AUTOSAR XML (schema 00049)
package /Application/DltConfig
  dlt log channel to process mapping DltLogChannelToProcessMapping_SOA_Power_TO_SOA_Power: dlt-log-channel=SOA_Power, process=SOA_Power
package /Application/Executable
  executable SOA_Power: category=APPLICATION_LEVEL, logging-behavior=USES-LOGGING, reporting-behavior=REPORTS-EXECUTION-STATE, version=1.0.0
    root sw component prototype AA: application-type=SOA_Power
package /Application/Manifest
  6 x service instance to port prototype mapping, all with process=SOA_Power:
    SOA_Power_AA_PPort_SOA_Power: port-prototype=AA.PPort_SOA_Power, service-instance=Provider_SoaPower
    SOA_Power_AA_RPort_Zone{1..4}RsvA: port-prototype=AA.RPort_Zone{1..4}RsvA, service-instance=Consumer_Zone{1..4}Rsv
    SOA_Power_AA_RPort_Zone5Power: port-prototype=AA.RPort_Zone5Power, service-instance=Consumer_Zone5Power
package /Application/Package/SOA_Power/SoftwareCluster_1_0_0
  software cluster SOA_Power_SoftwareCluster: category=APPLICATION_LAYER, contained-ar-element=SOA_Power, contained-package-element=[SOA_Power_AA_PPort_SOA_Power, SOA_Power_AA_RPort_Zone1RsvA, SOA_Power_AA_RPort_Zone2RsvA, SOA_Power_AA_RPort_Zone3RsvA, SOA_Power_AA_RPort_Zone4RsvA], contained-process=SOA_Power, vendor-id=79, vendor-signature=ParaCertificate, version=1.0.0
package /Application/Package/SOA_Power/SoftwareCluster_1_0_1
  software cluster SOA_Power_SoftwareCluster: category=APPLICATION_LAYER, contained-ar-element=SOA_Power, contained-package-element=[SOA_Power_AA_PPort_SOA_Power, SOA_Power_AA_RPort_Zone1RsvA, SOA_Power_AA_RPort_Zone2RsvA, SOA_Power_AA_RPort_Zone3RsvA, SOA_Power_AA_RPort_Zone4RsvA], contained-process=SOA_Power, vendor-id=79, vendor-signature=ParaCertificate, version=1.0.1
package /Application/Package/SOA_Power/SoftwareCluster_1_0_2
  software cluster SOA_Power_SoftwareCluster: category=APPLICATION_LAYER, contained-ar-element=SOA_Power, contained-package-element=[SOA_Power_AA_PPort_SOA_Power, SOA_Power_AA_RPort_Zone1RsvA, SOA_Power_AA_RPort_Zone2RsvA, SOA_Power_AA_RPort_Zone3RsvA, SOA_Power_AA_RPort_Zone4RsvA], contained-process=SOA_Power, vendor-id=79, vendor-signature=ParaCertificate, version=1.0.2
package /Application/Package/SOA_Power/SoftwarePackage
  software package SOA_Power_InstallSoftwarePackage_1_0_0: action-type=INSTALL, compressed-software-package-size=0, maximum-supported-ucm-version=1.0.0, minimum-supported-ucm-version=1.0.0, packager-id=79, packager-signature=ParaCertificate, post-verification-reboot=false, pre-activate=SC.Off, pre-activation-reboot=false, software-cluster=SoftwareCluster_1_0_0/SOA_Power_SoftwareCluster, uncompressed-software-cluster-size=0, verify=SC.Verify
  software package SOA_Power_RemoveSoftwarePackage_1_0_2: action-type=REMOVE, compressed-software-package-size=0, maximum-supported-ucm-version=1.0.0, minimum-supported-ucm-version=1.0.0, packager-id=79, packager-signature=ParaCertificate, post-verification-reboot=false, pre-activate=SC.Off, pre-activation-reboot=false, software-cluster=SoftwareCluster_1_0_2/SOA_Power_SoftwareCluster, uncompressed-software-cluster-size=0, verify=SC.Verify
  software package SOA_Power_UpdateSoftwarePackage_1_0_1: action-type=UPDATE, compressed-software-package-size=0, maximum-supported-ucm-version=1.0.0, minimum-supported-ucm-version=1.0.0, packager-id=79, packager-signature=ParaCertificate, post-verification-reboot=false, pre-activate=SC.Off, pre-activation-reboot=false, software-cluster=SoftwareCluster_1_0_1/SOA_Power_SoftwareCluster, uncompressed-software-cluster-size=0, verify=SC.Verify
package /Application/Package/SOA_Power/VehiclePackage
  vehicle package SOA_Power_InstallVehiclePackage_1_0_0: vehicle-driver-notification{approval-required=true, notification-state=PROCESS}, packager-signature=ParaCertificate
    rollout-qualifications:
      vehicle rollout step RolloutQualification0
        ucm-processings:
          ucm step UcmProcessing0: ucm=SOA_Power_InstallVehiclePackage_1_0_0/EEVP_UCM
            software package step SoftwarePackageStep0: process=SOA_Power_InstallSoftwarePackage_1_0_0, transfers=software-package-storing={storing=UCM, transfer=SOA_Power_InstallSoftwarePackage_1_0_0}
    ucm description EEVP_UCM: identifier=EEVP_UCM
  vehicle package SOA_Power_RemoveVehiclePackage_1_0_2: vehicle-driver-notification{approval-required=true, notification-state=PROCESS}, packager-signature=ParaCertificate
    rollout-qualifications:
      vehicle rollout step RolloutQualification0
        ucm-processings:
          ucm step UcmProcessing0: ucm=SOA_Power_RemoveVehiclePackage_1_0_2/EEVP_UCM
            software package step SoftwarePackageStep0: process=SOA_Power_RemoveSoftwarePackage_1_0_2, transfers=software-package-storing={storing=UCM, transfer=SOA_Power_RemoveSoftwarePackage_1_0_2}
    ucm description EEVP_UCM: identifier=EEVP_UCM
  vehicle package SOA_Power_UpdateVehiclePackage_1_0_1: vehicle-driver-notification{approval-required=true, notification-state=PROCESS}, packager-signature=ParaCertificate
    rollout-qualifications:
      vehicle rollout step RolloutQualification0
        ucm-processings:
          ucm step UcmProcessing0: ucm=SOA_Power_UpdateVehiclePackage_1_0_1/EEVP_UCM
            software package step SoftwarePackageStep0: process=SOA_Power_UpdateSoftwarePackage_1_0_1, transfers=software-package-storing={storing=UCM, transfer=SOA_Power_UpdateSoftwarePackage_1_0_1}
    ucm description EEVP_UCM: identifier=EEVP_UCM
package /Application/Process
  process SOA_Power: executable=SOA_Power, state-dependent-startup-config{function-group-state=[SC.On, SC.Verify], resource-group=DefaultResourceGroup, startup-config=SOA}
    process state machine SOA_Power: type=ProcessState
package /Application/SwComponent
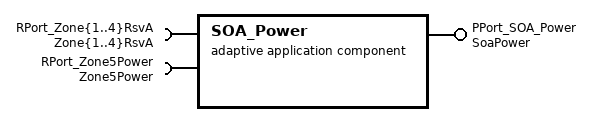
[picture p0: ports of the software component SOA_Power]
  adaptive application sw component type SOA_Power
    provide port PPort_SOA_Power: provided-interface=SoaPower
    5 x require port:
      RPort_Zone{1..4}RsvA: required-interface=Zone{1..4}RsvA
      RPort_Zone5Power: required-interface=Zone5Power
